# RTS5918 register map
Vendor: Realtek Semiconductor Corp.; Series: RTS5918 Series; File version: 1.00
CPU: ARMV8MML r0p0, little endian, MPU, FPU, VTOR, 3 interrupt priority bits, 8 SAU regions
Registers are 32-bit, read-write, reset 0x0 unless marked. A register's access mark holds for its fields unless they carry their own. Offsets are from the block's base; [hi:lo] are bit positions; {n}, {i} and the like mark numbered series; 'fields as' and 'values as' point back to an identical list.

## SHA2DMA — Lalu SHA2 DMA Controller
Base 0x40041000
Same registers: AESDMA 0x40044000
0x00 SAR — SOURCE ADDRESS REGISTER
0x08 DAR — DESTINATION ADDRESS REGISTER
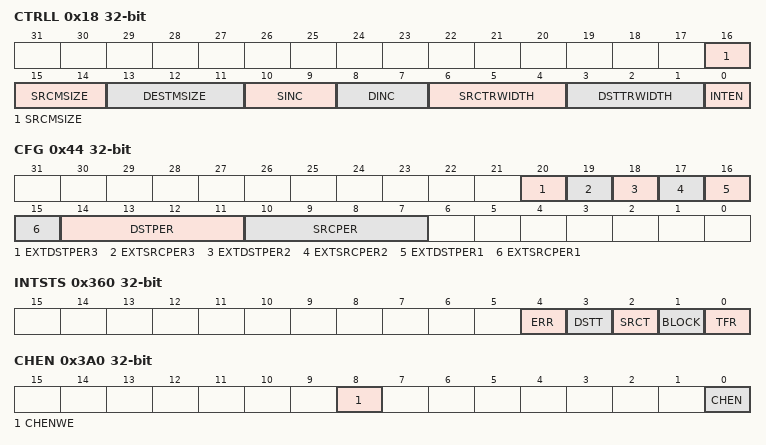
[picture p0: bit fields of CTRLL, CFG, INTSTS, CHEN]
0x18 CTRLL — CONTROL REGISTER LOW
  [16:14] SRCMSIZE — Source Burst Transaction Length
  [13:11] DESTMSIZE — Destination Burst Transaction Length
  [10:9] SINC — Source Address Increment
  [8:7] DINC — Destination Address Increment
  [6:4] SRCTRWIDTH — Source Transfer Width
  [3:1] DSTTRWIDTH — Destination Transfer Width
  [0] INTEN — Interrupt Enable Bit
    0=DISABLE (Disable interrup); 1=ENABLE (Enable interrup)
0x1C CTRLH — CONTROL REGISTER HIGH
  [11:0] BLOCKTS — Block Transfer Size
0x44 CFG — CONFIGURATION REGISTER
  [20] EXTDSTPER3 — The extened 6th bit of DSTPER
  [19] EXTSRCPER3 — The extened 6th bit of SRCPER
  [18] EXTDSTPER2 — The extened 5th bit of DSTPER
  [17] EXTSRCPER2 — The extened 5th bit of SRCPER
  [16] EXTDSTPER1 — The extened 4th bit of DSTPER
  [15] EXTSRCPER1 — The extened 4th bit of SRCPER
  [14:11] DSTPER — Assigns a Hardware Handshaking Interface to The Destination of Channel
  [10:7] SRCPER — Assigns a Hardware Handshaking Interface to The Source of Channel
0x310 MSKTFR — MASK FOR INTTFR INTERRUPT REGISTER
0x338 CLRTFR — CLEAR INTERRUPT STATUS FOR INTTFR INTERRUPT REGISTER
0x360 INTSTS ro — COMBINED INTERRUPT SATAUS REGISTER
  [4] ERR — OR of The Contents of StatusErr Register
  [3] DSTT — OR of The Contents of StatusDst Register
  [2] SRCT — OR of The Contents of StatusSrcTran Register
  [1] BLOCK — OR of The Contents of StatusBlock Register
  [0] TFR — OR of The Contents of StatusTfr Register
0x398 CONF — CONFIGURATION REGISTER
  [0] EN — Enable DMA Controller
    0=DISABLE (Disable DMA Controller); 1=ENABLE (Enable DMA Controller)
0x3A0 CHEN — CHANNEL ENABLE REGISTER
  [8] CHENWE — Enables Channel Write Enable
    0=DISABLE (Dsiable channel write enable); 1=ENABLE (Enables channel write enable)
  [0] CHEN — Enables DMA Channel
    0=DISABLE (Dsiable DMA Channel); 1=ENABLE (Enables DMA Channel)

## SHA3 — Lalu SHA3 Engine
Base 0x40002000
0x00 DINADDR — INPUT DATA ADDRESS REGISTER
0x04 DINLEN — DATA LENGTH REGISTER
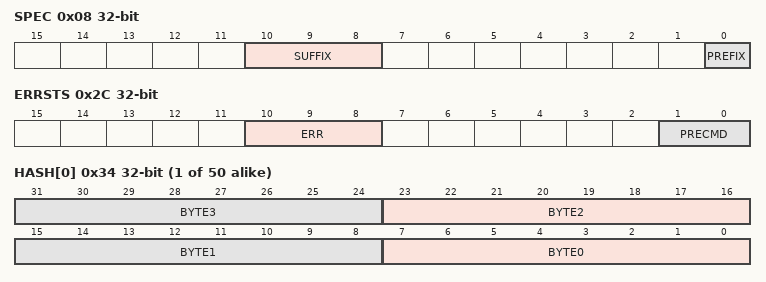
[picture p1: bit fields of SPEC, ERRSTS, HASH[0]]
0x08 SPEC — SPECIFICATION REGISTER
  [10:8] SUFFIX — Suffix Of SHA3 Specification
    0=SHAKE_128 (Select SHAKE128); 1=SHA3_224 (Select SHA3-224); 2=SHA3_256 (Select SHA3-256); 3=SHA3_384 (Select SHA3-384); 4=SHA3_512 (Select SHA3-512)
  [0] PREFIX — SHA3 Or SHAKE Selection
    0=SHA3 (Select SHA3); 1=SHAKE (Select SHAKE)
0x0C INTDIS — INTERRUPT DISABLE REGISTER
0x10 LPMDDIS — LOW POWER MODE DISABLE REGISTER
0x14 ENABLE
  [1:0] EN — Enable SHA3 Engine To Execute Command
    1=UPDATE (SHA3 engine DMA starts to receive input data); 2=FINALIZE (SHA3 engine attches padding data and generate HASH data); other=NOT_USED (Reserved values. Do not use.)
0x18 CLR — CLEAR HASH VALUE AND INPUT BUFFER REGISTER
0x20 SQUEEZE
0x2C ERRSTS — ERROR STATUS REGISTER
  [10:8] ERR — Error Status
    0=NO_ERR (No error); 1=DMA (DMA error); 2=Busy error; 3=CONFLICT (Conflict error); 4=OVER_WRITEN (Over-writen error)
  [1:0] PRECMD — Latest Command
    0=CLEAR (Clear SHA3); 1=UPDATE; 2=FINALIZE; 3=SQUEEZE
0x30 ADDRERR — READ ERROR ADDRESS REGISTER
{0x34+4i} HASH[{i}] (i=0..49) — HASH VALUE REGISTER
  [8n+7:8n] BYTE{n} (n=0..3) — Hash value, byte{n}

## AES — Lalu AES Engine
Base 0x40043000
Same registers: AES2 0x40044000
0x00 DATAIN{x} (x=3,2,1,0; step 0x4) — DATA IN REGISTER #{x}
0x10 DATAOUT{x} (x=3,2,1,0; step 0x4) — DATA OUT REGISTER #{x}
0x20 KEYDEAOUT{x} (x=7,6,5,4,3,2,1,0; step 0x4) — DECRYPTION KEY REGISTER #{x}
0x40 KEY{x} (x=7,6,5,4,3,2,1,0; step 0x4) — KEY REGISTER #{x}
0x60 IV{x} (x=3,2,1,0; step 0x4) — IV REGISTER #{x}
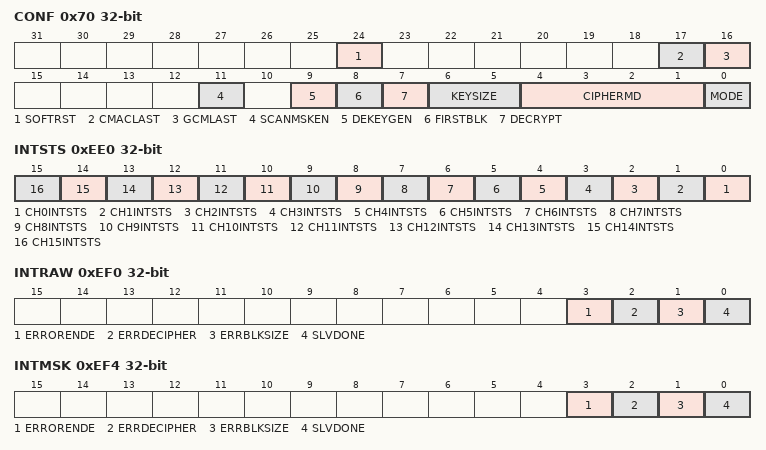
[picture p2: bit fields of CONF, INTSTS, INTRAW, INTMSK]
0x70 CONF — CONFIGURATION REGISTER
  [24] SOFTRST — Software Reset
  [17] CMACLAST — Indicated The Last Block
  [16] GCMLAST — Indicated The Last Block
  [11] SCANMSKEN — SCA Mask Enable
  [9] DEKEYGEN — Generate A Key When Decrypting
  [8] FIRSTBLK — First Block
  [7] DECRYPT — Decrypt/Encrypt Selection
    0=DECRYPT (Select decrypt mode); 1=ENCRYPT (Select encrypt mode)
  [6:5] KEYSIZE — Key Size Selection
    0=128_BIT (Select 128-bit); 1=192_BIT (Select 192-bit); 2=256_BIT (Select 256-bit); other=NOT_USED (Reserved values. Do not use.)
  [4:1] CIPHERMD — Cipher Mode Selection
    0=ECB (Select ECB mode); 1=CBC (Select CBC mode); 2=CFB (Select CFB mode); 3=OFB (Select OFB mode); 4=CTR (Select CTR mode); 5=GMAC (Select GMAC mode); 6=GCM (Select GCM mode); 7=CMAC (Select CMAC mode); 8=XTS (Select XTS mode); other=NOT_USED (Reserved values. Do not use.)
  [0] MODE — Engnie Mode Selection
    0=SLV (Select slave mode); 1=DMA (Select dma mode)
0x74 LEN — INPUT LENGTH REGISTER
0x78 GMACLEN{x} (x=1,0; step 0x4) — AAD LENGTH REGISTER #{x}
0x80 TAG{x} (x=3,2,1,0; step 0x4) — TAG REGISTER #{x}
0x90 GHASHKEY{x} (x=3,2,1,0; step 0x4) — GHASH KEY REGISTER #{x}
0xEE0 INTSTS — INTERRUPT STATUS REGISTER
  [n] CH{n}INTSTS (n=0..15) — Channel Interrupt Status
0xEF0 INTRAW ro — RAW INTERRUPT STATUS REGISTER
  [3] ERRORENDE — User Uses Operation When Closing
  [2] ERRDECIPHER — User Set a Non-Existent Cipher Mode
  [1] ERRBLKSIZE — Input size is a multiple of 128
  [0] SLVDONE — Slave Mode Completes AES
0xEF4 INTMSK — ENABLE INTERRUPT REGISTER
  [3] ERRORENDE — Enable ERRORENDE Interrupt
  [2] ERRDECIPHER — Enable ERRDECIPHER Interrupt
  [1] ERRBLKSIZE — Enable ERRBLKSIZE Interrupt
  [0] SLVDONE — Enable SLVDONE Interrupt
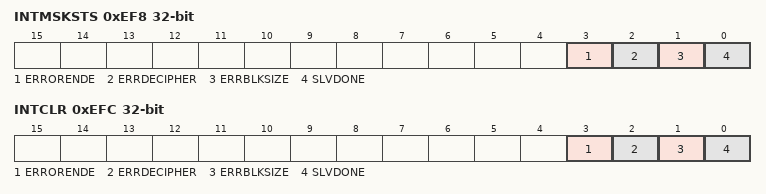
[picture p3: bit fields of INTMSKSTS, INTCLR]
0xEF8 INTMSKSTS — MASKED INTERRUPT STATUS REGISTER
  fields as INTRAW
0xEFC INTCLR — CLEAR INTERRUPT REGISTER
  [3] ERRORENDE — Clear ERRORENDE Interrupt
  [2] ERRDECIPHER — Clear ERRDECIPHER Interrupt
  [1] ERRBLKSIZE — Clear ERRBLKSIZE Interrupt
  [0] SLVDONE — Clear SLVDONE Interrupt

## Notices in the file
The license belong to Realtek Semiconductor Corp. All the rights reserved.
